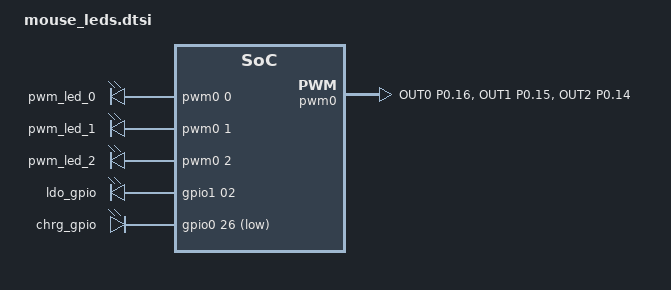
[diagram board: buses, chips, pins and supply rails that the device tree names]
&pinctrl {
	// Other Pinctrl definitions go here
	pwm0_default: pwm0_default {
		group1 {
			psels = <NRF_PSEL(PWM_OUT0, 0, 16)>,// RED
			<NRF_PSEL(PWM_OUT1, 0, 15)>,// GREEN
			<NRF_PSEL(PWM_OUT2, 0, 14)>;// BLUE
		};
	};
	pwm0_sleep: pwm0_sleep {
		group1 {
			psels = <NRF_PSEL(PWM_OUT0, 0, 16)>,// RED
			<NRF_PSEL(PWM_OUT1, 0, 15)>,// GREEN
			<NRF_PSEL(PWM_OUT2, 0, 14)>;// BLUE
			low-power-enable;
		};
	};
};

&pwm0 {
	status = "okay";
	pinctrl-0 = <&pwm0_default>;
	pinctrl-1 = <&pwm0_sleep>;
	pinctrl-names = "default", "sleep";
};

/ {
	backlight: pwmleds {
		compatible = "pwm-leds";
		pwm_led_0: pwm_led_0 {
			pwms = <&pwm0 0 PWM_MSEC(10) PWM_POLARITY_INVERTED>;
		};
		pwm_led_1: pwm_led_1 {
			pwms = <&pwm0 1 PWM_MSEC(10) PWM_POLARITY_INVERTED>;
		};
		pwm_led_2: pwm_led_2 {
			pwms = <&pwm0 2 PWM_MSEC(10) PWM_POLARITY_INVERTED>;
		};
	};
	
	additional_gpio: additional_gpio {
		compatible = "gpio-leds";
		ldo_gpio: ldo_gpio {
			gpios = <&gpio1 02 GPIO_ACTIVE_HIGH>;
		};
		chrg_gpio: chrg_gpio {
			gpios = <&gpio0 26 (GPIO_ACTIVE_LOW | GPIO_PULL_UP)>;
		};
	};
	
	aliases {
		led0 = &pwm_led_0;
		led1 = &pwm_led_1;
		led2 = &pwm_led_2;
		ldo  = &ldo_gpio;
		chrg = &chrg_gpio;
	};
};
